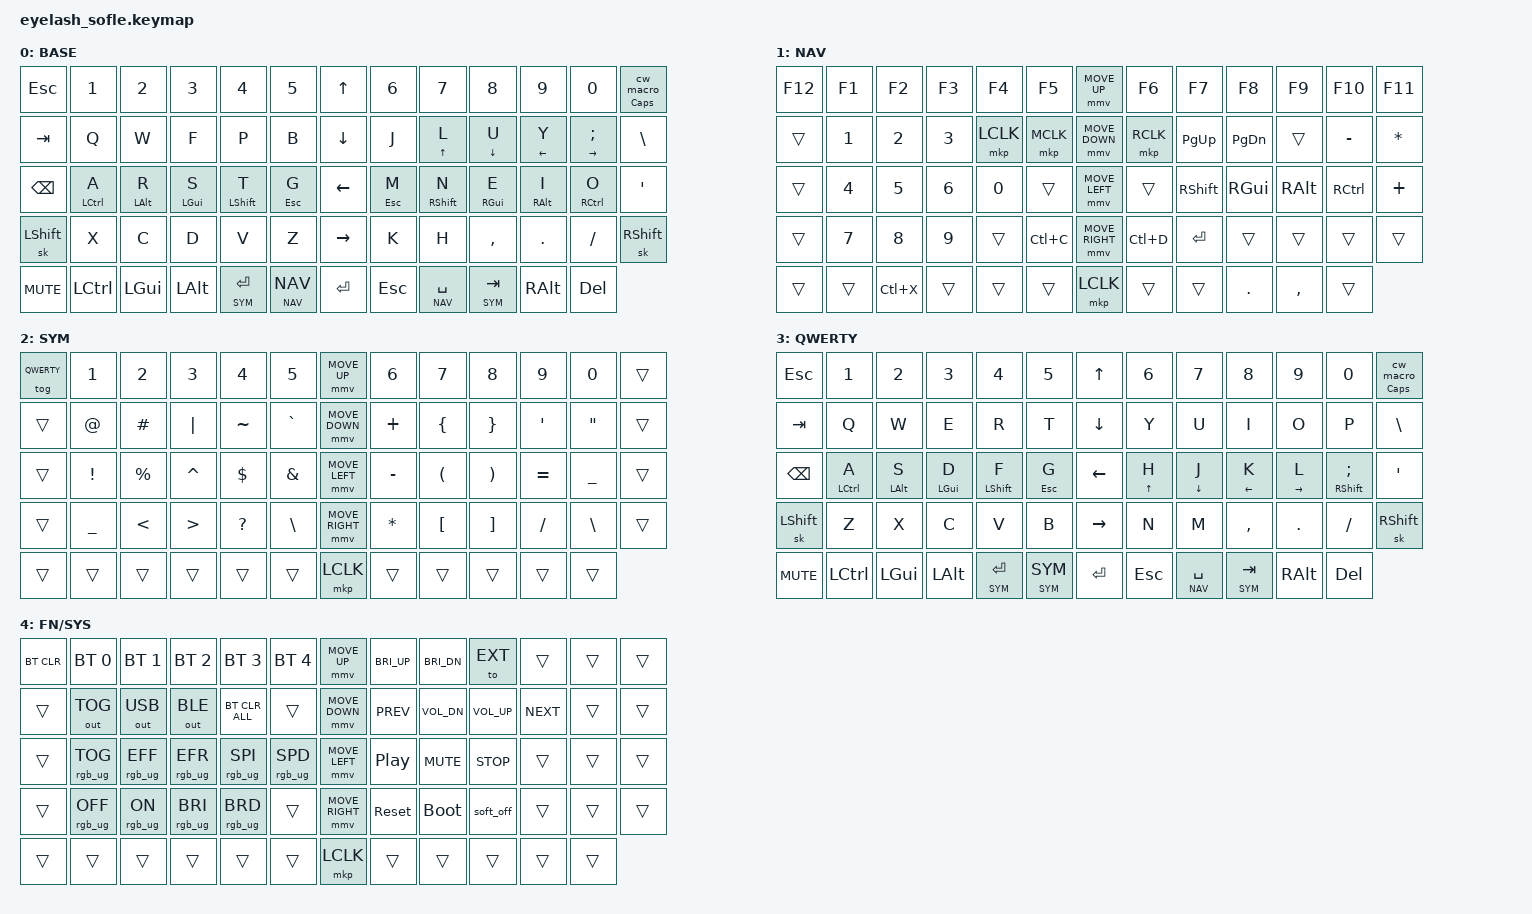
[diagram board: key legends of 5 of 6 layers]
/*
 * Eyelash Sofle — ZMK keymap (synchronized with kanata.kbd)
 *
 * Layers:
 *   0 = BASE    Colemak-DH + HRMs + top-row hold-arrows
 *   1 = NAV     Navigation / numpad / clipboard shortcuts
 *   2 = SYM     Symbols (+ pos 0 toggles QWERTY)
 *   3 = QWERTY  QWERTY alpha layer (toggle via SYM, pos 0)
 *   4 = FN      Function / media / BT / RGB / system (tri-layer NAV+SYM)
 *   5 = EXT     Extended / special keys (toggle via FN, &to EXT)
 *
 * Thumb cluster (outer -> inner, 6 per side):
 *   L: MUTE | CTRL | GUI | ALT | ENTER/SYM | NAV (mo/sticky)
 *   R: ENTER | ESC | SPACE/NAV | TAB/SYM | RALT | DEL
 *
 * Home-row & top-row holds (BASE Colemak-DH):
 *   L (mods):   A=Ctrl  R=Alt  S=GUI  T=Shift (hsl)   G=ESC (hla)
 *   R (arrows): L=UP    U=DOWN  Y=LEFT  ;=RIGHT (top row)
 *   R (mods):   M=ESC   N=Shift (hsr)  E=GUI (hmr)  I=Alt (hmr)  O=Ctrl (hmr) (home row)
 *
 * Home-row holds (QWERTY):
 *   L (mods):   A=Ctrl  S=Alt  D=GUI  F=Shift (hsl)   G=ESC (hla)
 *   R (arrows): H=UP    J=DOWN  K=LEFT  L=RIGHT  ;=Shift (hsr)
 *
 * Combos (DISABLED — kept in source for easy re-enable):
 *   J+K       -> ESC
 *   M+,       -> TAB
 *   C+V       -> Caps Word
 *   14+28+40  -> soft_off (power down)
 */

#define ZMK_POINTING_DEFAULT_MOVE_VAL 1200
#define ZMK_POINTING_DEFAULT_SCRL_VAL 25

#include <input/processors.dtsi>
#include <zephyr/dt-bindings/input/input-event-codes.h>
#include <behaviors.dtsi>
#include <dt-bindings/zmk/bt.h>
#include <dt-bindings/zmk/keys.h>
#include <dt-bindings/zmk/outputs.h>
#include <dt-bindings/zmk/pointing.h>
#include <dt-bindings/zmk/rgb.h>

/* Layer aliases (must match declaration order in keymap { } below). */
#define BASE   0
#define NAV    1
#define SYM    2
#define QWERTY 3
#define FN     4
#define EXT    5

/* ---- Reusable row fragments (expanded by the C preprocessor) ----
 * Edit a fragment here and every layer that uses it updates at once. */
#define LMODS  &kp LCTRL &kp LALT &kp LGUI &kp LSHFT               /* row3 mods, pos 27-30 */
#define EDIT   &kp K_UNDO &kp K_CUT &kp K_COPY &kp K_PASTE &kp K_REDO /* row4 edit, pos 40-44 */

/* Trackball center column (one binding per row; centralized for retuning). */
#define TB_U   &mmv MOVE_UP
#define TB_D   &mmv MOVE_DOWN
#define TB_L   &mmv MOVE_LEFT
#define TB_R   &mmv MOVE_RIGHT
#define TB_CLK &mkp LCLK

/* ------------------------------------------------------------------
 * Pointing devices (trackball + scroll wheel) — kept from prior tuning.
 * ------------------------------------------------------------------ */
&mmv_input_listener { input-processors = <&zip_xy_scaler 2 1>; };
&msc_input_listener { input-processors = <&zip_scroll_scaler 2 1>; };

&msc {
    acceleration-exponent = <1>;
    time-to-max-speed-ms  = <100>;
    delay-ms              = <0>;
};

&mmv {
    time-to-max-speed-ms  = <500>;
    acceleration-exponent = <1>;
    trigger-period-ms     = <16>;
};

&soft_off { hold-time-ms = <2000>; };

/* Caps-word continuation: let it survive common word separators. */
&caps_word { continue-list = <UNDERSCORE MINUS BACKSPACE DELETE>; };

/* Sticky keys ignore other modifiers — allows sequential sticky stacking
 * (e.g. hold A=Ctrl, release, hold R=Alt, release, tap key → Ctrl+Alt+key). */
&sk { ignore-modifiers; };

/ {
    /* Tri-layer: holding NAV and SYM simultaneously activates FN. */
    conditional_layers {
        compatible = "zmk,conditional-layers";
        tri_layer {
            if-layers = <NAV SYM>;
            then-layer = <FN>;
        };
    };

    scroll_encoder: scroll_encoder {
        compatible = "zmk,behavior-sensor-rotate";
        #sensor-binding-cells = <0>;
        bindings = <&msc SCRL_DOWN>, <&msc SCRL_UP>;
        tap-ms = <100>;
    };

    behaviors {
        /* Home-row mods (left hand) — Ctrl / Alt / GUI only (A / R / S).
         *
         *   Tap  = letter
         *   Hold + other key + release  = Ctrl/Alt/GUI + that key
         *   Hold + release alone        = sticky mod for the NEXT keypress only
         *
         * - balanced flavor is forgiving for fast typists
         * - require-prior-idle-ms prevents mods after rolling letters
         *   (kept strict at 150 — you press these deliberately, with a pause;
         *    SHIFT is split onto `hsl` below so fast-typing holds still register)
         * - hold-trigger-key-positions = only the OTHER hand
         * - hold-trigger-on-release keeps rolls from accidentally modding
         */
        hml: home_row_mod_left {
            compatible = "zmk,behavior-hold-tap";
            #binding-cells = <2>;
            flavor = "balanced";
            tapping-term-ms = <220>;
            quick-tap-ms = <175>;
            require-prior-idle-ms = <150>;
            bindings = <&sk>, <&kp>;
            hold-trigger-key-positions = <
                /* Full right hand */
                6  7  8  9  10 11 12
                19 20 21 22 23 24 25
                32 33 34 35 36 37 38
                45 46 47 48 49 50 51
                58 59 60 61 62 63
                /* Other left-hand HRM keys — A+R+S+T can chord together */
                27 28 29 30
            >;
            hold-trigger-on-release;
        };

        /* Left-hand SHIFT (T on Colemak, F on QWERTY) — same as hml but tuned
         * so a deliberate long-press registers even in the middle of a fast
         * burst. require-prior-idle-ms is removed (0) because Shift is the one
         * mod you fire mid-word to capitalize, so it must NOT be force-resolved
         * to a tap just because you pressed a key <150ms earlier.
         *
         * Roll protection is still provided by the opposite-hand positional
         * guard + hold-trigger-on-release (same-hand rolls won't shift).
         * If you ever get accidental capitals on fast opposite-hand rolls,
         * raise require-prior-idle-ms here to ~50.
         */
        hsl: home_shift_left {
            compatible = "zmk,behavior-hold-tap";
            #binding-cells = <2>;
            flavor = "balanced";
            tapping-term-ms = <220>;
            quick-tap-ms = <175>;
            require-prior-idle-ms = <0>;
            bindings = <&sk>, <&kp>;
            hold-trigger-key-positions = <
                /* Full right hand */
                6  7  8  9  10 11 12
                19 20 21 22 23 24 25
                32 33 34 35 36 37 38
                45 46 47 48 49 50 51
                58 59 60 61 62 63
                /* Other left-hand HRM keys — can chord together */
                27 28 29 30
            >;
            hold-trigger-on-release;
        };

        /* Right-hand mods (E=GUI, I=Alt, O=Ctrl on Colemak). */
        hmr: home_row_mod_right {
            compatible = "zmk,behavior-hold-tap";
            #binding-cells = <2>;
            flavor = "balanced";
            tapping-term-ms = <220>;
            quick-tap-ms = <175>;
            require-prior-idle-ms = <150>;
            bindings = <&sk>, <&kp>;
            hold-trigger-key-positions = <
                0  1  2  3  4  5
                13 14 15 16 17 18
                26 27 28 29 30 31
                39 40 41 42 43 44
                52 53 54 55 56 57
                /* Other right-hand HRM keys — can chord together */
                34 35 36 37
            >;
            hold-trigger-on-release;
        };

        /* Right-hand SHIFT (N on Colemak, ; on QWERTY).
         * require-prior-idle-ms is 0 so fast capitalizations work mid-burst. */
        hsr: home_shift_right {
            compatible = "zmk,behavior-hold-tap";
            #binding-cells = <2>;
            flavor = "balanced";
            tapping-term-ms = <220>;
            quick-tap-ms = <175>;
            require-prior-idle-ms = <0>;
            bindings = <&sk>, <&kp>;
            hold-trigger-key-positions = <
                0  1  2  3  4  5
                13 14 15 16 17 18
                26 27 28 29 30 31
                39 40 41 42 43 44
                52 53 54 55 56 57
                /* Other right-hand HRM keys — can chord together */
                34 35 36 37
            >;
            hold-trigger-on-release;
        };

        /* Right-hand hold-arrows (top row Colemak, home row QWERTY) & hold-ESC (M):
         * tap = letter, hold = arrow/esc.
         * Opposite-hand guard ensures same-hand rolls type letters rather than firing arrows.
         */
        hra: home_row_arrow {
            compatible = "zmk,behavior-hold-tap";
            #binding-cells = <2>;
            flavor = "balanced";
            tapping-term-ms = <200>;
            quick-tap-ms = <175>;
            require-prior-idle-ms = <150>;
            bindings = <&kp>, <&kp>;
            hold-trigger-key-positions = <
                0  1  2  3  4  5
                13 14 15 16 17 18
                26 27 28 29 30 31
                39 40 41 42 43 44
                52 53 54 55 56 57
            >;
            hold-trigger-on-release;
        };

        /* Left-hand hold-arrow: same as hra but triggers on RIGHT hand.
         * Used for G=ESC (left inner column, needs right-hand pairing).
         * Used ONLY by G, so require-prior-idle-ms is set to 0 directly so a
         * long-press reliably yields Esc during fast typing.
         */
        hla: home_left_arrow {
            compatible = "zmk,behavior-hold-tap";
            #binding-cells = <2>;
            flavor = "balanced";
            tapping-term-ms = <200>;
            quick-tap-ms = <175>;
            require-prior-idle-ms = <0>;
            bindings = <&kp>, <&kp>;
            hold-trigger-key-positions = <
                6  7  8  9  10 11 12
                19 20 21 22 23 24 25
                32 33 34 35 36 37 38
                45 46 47 48 49 50 51
                58 59 60 61 62 63
            >;
            hold-trigger-on-release;
        };

        /* Layer-tap tuned for thumbs: snappier hold. */
        lt_thumb: layer_tap_thumb {
            compatible = "zmk,behavior-hold-tap";
            #binding-cells = <2>;
            flavor = "tap-preferred";
            tapping-term-ms = <180>;
            quick-tap-ms = <150>;
            bindings = <&mo>, <&kp>;
        };

        /* "Smart" layer thumb:
         *   hold = momentary layer (&mo)
         *   tap  = sticky one-shot layer (&sl)
         *
         * Usage: &ltq <layer> <layer>    (same layer twice)
         *
         * Behavior:
         *   - Press and hold → layer is active while held, releases when you let go
         *     (standard momentary).
         *   - Quick press and release (< tapping-term-ms) with NO other key pressed
         *     → layer is sticky: the very next keypress is interpreted on that layer,
         *     then the layer auto-releases.
         *   - Press, then press another key before releasing → acts as momentary
         *     (the held-down layer is what the other key lands on).
         *
         * "balanced" flavor + quick-tap-ms=0 so consecutive taps feel predictable.
         */
        ltq: layer_tap_or_sticky {
            compatible = "zmk,behavior-hold-tap";
            #binding-cells = <2>;
            flavor = "balanced";
            tapping-term-ms = <200>;
            quick-tap-ms = <0>;
            bindings = <&mo>, <&sl>;
        };

        /* Tap = kp, Hold = sticky layer.
         *
         *   Usage: &kp_slh <layer> <keycode>
         *
         *   - Quick tap and release               → kp (e.g. ENTER)
         *   - Hold past tapping term, press key   → that key lands on <layer>
         *     (feels like a momentary layer — sticky fires first, next key uses it)
         *   - Hold past tapping term, release     → <layer> is sticky for the next
         *     keypress; then auto-releases.
         *
         *   'balanced' + require-prior-idle-ms keep it from firing as a sticky layer
         *   during fast typing.
         */
        kp_slh: kp_tap_sticky_layer_hold {
            compatible = "zmk,behavior-hold-tap";
            #binding-cells = <2>;
            flavor = "balanced";
            tapping-term-ms = <150>;
            quick-tap-ms = <120>;
            require-prior-idle-ms = <100>;
            bindings = <&sl>, <&kp>;
        };

        /* Tap = Caps Word, Hold = Caps Lock.
         *
         *   Usage: &cw_caps CAPS 0
         *     - hold side (&kp) receives CAPS  -> tap-and-hold = Caps Lock
         *     - tap  side (&cw_macro) receives the dummy 0, which it ignores,
         *       and fires &caps_word.
         *
         * Why the macro? &caps_word is a zero-parameter behavior, so it cannot
         * sit directly in a hold-tap's tap slot (the hold-tap always feeds one
         * parameter to each side, exactly like `ltq` does with &mo/&sl). The
         * one-param macro `cw_macro` below absorbs that parameter so caps_word
         * can be nested.
         *
         * tap-preferred so a quick tap reliably yields Caps Word, while a
         * deliberate hold gives Caps Lock (holding also sidesteps the macOS
         * "caps tapped too fast doesn't register" quirk, since hold is longer).
         */
        cw_caps: caps_word_tap_caps_hold {
            compatible = "zmk,behavior-hold-tap";
            #binding-cells = <2>;
            flavor = "tap-preferred";
            tapping-term-ms = <200>;
            quick-tap-ms = <150>;
            bindings = <&kp>, <&cw_macro>;
        };
    };

    macros {
        /* One-parameter wrapper so the zero-param &caps_word behavior can be
         * placed in a hold-tap's tap slot (see cw_caps above). The incoming
         * parameter is accepted to satisfy the cell count and then ignored. */
        cw_macro: cw_macro {
            compatible = "zmk,behavior-macro-one-param";
            #binding-cells = <1>;
            bindings = <&caps_word>;
        };
    };

/*
*    combos {
*        compatible = "zmk,combos";
*
*        combo_softoff {
*            bindings = <&soft_off>;
*            key-positions = <14 28 40>;
*            layers = <BASE QWERTY>;
*        };
*
*        combo_esc {
*            bindings = <&kp ESC>;
*            key-positions = <20 21>;   // J + K
*            timeout-ms = <40>;
*            layers = <BASE QWERTY>;
*        };
*
*        combo_tab {
*            bindings = <&kp TAB>;
*            key-positions = <34 35>;   // M + ,
*            timeout-ms = <40>;
*            layers = <BASE QWERTY>;
*        };
*
*        combo_caps_word {
*            bindings = <&caps_word>;
*            key-positions = <29 30>;   // C + V
*            timeout-ms = <40>;
*            layers = <BASE QWERTY>;
*        };
*    };
*/

    keymap {
        compatible = "zmk,keymap";

        /* ==================================================================
         * LAYER 0 — BASE (Colemak-DH)
         * ================================================================== */
        base_layer {
            display-name = "BASE";
            bindings = <
&kp ESC        &kp N1         &kp N2         &kp N3        &kp N4              &kp N5            &kp UP_ARROW      &kp N6              &kp N7         &kp N8        &kp N9         &kp N0            &cw_caps CAPS 0
&kp TAB        &kp Q          &kp W          &kp F         &kp P               &kp B             &kp DOWN_ARROW    &kp J               &hra UP L      &hra DOWN U   &hra LEFT Y    &hra RIGHT SEMI   &kp BSLH
&kp BACKSPACE  &hml LCTRL A   &hml LALT R    &hml LGUI S   &hsl LSHFT T        &hla ESC G        &kp LEFT_ARROW    &hra ESC M          &hsr RSHFT N   &hmr RGUI E   &hmr RALT I    &hmr RCTRL O      &kp APOS
&sk LSHFT      &kp X          &kp C          &kp D         &kp V               &kp Z             &kp RIGHT_ARROW   &kp K               &kp H          &kp COMMA     &kp DOT        &kp FSLH          &sk RSHFT
&kp C_MUTE     &kp LCTRL      &kp LGUI       &kp LALT      &kp_slh SYM ENTER   &ltq NAV NAV      &kp ENTER         &kp ESC   &kp_slh NAV SPACE        &lt_thumb SYM TAB  &kp RALT  &kp DEL
            >;
            sensor-bindings = <&inc_dec_kp C_VOLUME_UP C_VOL_DN>;
        };

        /* ==================================================================
         * LAYER 1 — NAV
         *   Mirrors kanata.kbd nav layer:
         *   - Left hand: Numpad (1-9), mouse clicks (L/M/R), Cut/Copy/Dup
         *   - Right hand: PgUp/PgDn, mods (Shift/GUI/Alt/Ctrl), Return, +, *
         * ================================================================== */
        nav_layer {
            display-name = "NAV";
            bindings = <
&kp F12     &kp F1      &kp F2      &kp F3      &kp F4      &kp F5      TB_U     &kp F6      &kp F7      &kp F8      &kp F9      &kp F10     &kp F11
&trans      &kp N1      &kp N2      &kp N3      &mkp LCLK   &mkp MCLK   TB_D     &mkp RCLK   &kp PG_UP   &kp PG_DN   &trans      &kp MINUS   &kp ASTRK
&trans      &kp N4      &kp N5      &kp N6      &kp N0      &trans      TB_L     &trans      &kp RSHFT   &kp RGUI    &kp RALT    &kp RCTRL   &kp PLUS
&trans      &kp N7      &kp N8      &kp N9      &trans      &kp LC(C)   TB_R     &kp LC(D)   &kp ENTER   &trans      &trans      &trans      &trans
&trans      &trans      &kp LC(X)   &trans      &trans      &trans      TB_CLK   &trans      &trans      &kp DOT     &kp COMMA   &trans
            >;
            sensor-bindings = <&scroll_encoder>;
        };

        /* ==================================================================
         * LAYER 2 — SYM
         *   Top-left (pos 0) toggles QWERTY (mirrors kanata @tog_qw).
         *   Symbol layout mirrors kanata.kbd.
         * ================================================================== */
        sym_layer {
            display-name = "SYM";
            bindings = <
&tog QWERTY     &kp N1      &kp N2      &kp N3      &kp N4      &kp N5      TB_U     &kp N6       &kp N7       &kp N8       &kp N9       &kp N0       &trans
&trans          &kp AT     &kp HASH    &kp PIPE    &kp TILDE   &kp GRAVE   TB_D     &kp PLUS     &kp LBRC     &kp RBRC     &kp APOS     &kp DQT      &trans
&trans          &kp EXCL   &kp PRCNT   &kp CARET   &kp DLLR    &kp AMPS    TB_L     &kp MINUS    &kp LPAR     &kp RPAR     &kp EQUAL    &kp UNDER    &trans
&trans          &kp UNDER  &kp LT      &kp GT      &kp QMARK   &kp BSLH    TB_R     &kp ASTRK    &kp LBKT     &kp RBKT     &kp FSLH     &kp BSLH     &trans
&trans          &trans     &trans      &trans      &trans      &trans      TB_CLK   &trans       &trans       &trans       &trans       &trans
            >;
            sensor-bindings = <&scroll_encoder>;
        };

        /* ==================================================================
         * LAYER 3 — QWERTY (toggle via SYM pos 0)
         *   Thumb cluster opens SYM; SYM pos 0 (&tog QWERTY) toggles back to BASE.
         * ================================================================== */
        qwerty_layer {
            display-name = "QWERTY";
            bindings = <
&kp ESC        &kp N1         &kp N2        &kp N3         &kp N4              &kp N5            &kp UP_ARROW      &kp N6              &kp N7         &kp N8        &kp N9         &kp N0            &cw_caps CAPS 0
&kp TAB        &kp Q          &kp W         &kp E          &kp R               &kp T             &kp DOWN_ARROW    &kp Y               &kp U          &kp I         &kp O          &kp P             &kp BSLH
&kp BACKSPACE  &hml LCTRL A   &hml LALT S   &hml LGUI D    &hsl LSHFT F        &hla ESC G        &kp LEFT_ARROW    &hra UP H           &hra DOWN J    &hra LEFT K   &hra RIGHT L   &hsr RSHFT SEMI   &kp APOS
&sk LSHFT      &kp Z          &kp X         &kp C          &kp V               &kp B             &kp RIGHT_ARROW   &kp N               &kp M          &kp COMMA     &kp DOT        &kp FSLH          &sk RSHFT
&kp C_MUTE     &kp LCTRL      &kp LGUI      &kp LALT       &kp_slh SYM ENTER   &ltq SYM SYM      &kp ENTER         &kp ESC   &kp_slh NAV SPACE        &lt_thumb SYM TAB   &kp RALT  &kp DEL
            >;
            sensor-bindings = <&inc_dec_kp C_VOLUME_UP C_VOL_DN>;
        };

        /* ==================================================================
         * LAYER 4 — FN / Media / System / BT   (tri-layer NAV+SYM)
         *   All the "rare" stuff: bluetooth, RGB, resets, output toggle,
         *   media controls.
         * ================================================================== */
        fn_layer {
            display-name = "FN/SYS";
            bindings = <
&bt BT_CLR &bt BT_SEL 0     &bt BT_SEL 1      &bt BT_SEL 2     &bt BT_SEL 3     &bt BT_SEL 4      TB_U             &kp C_BRI_UP  &kp C_BRI_DN  &to EXT      &trans  &trans  &trans
&trans     &out OUT_TOG     &out OUT_USB      &out OUT_BLE     &bt BT_CLR_ALL   &trans            TB_D             &kp C_PREV    &kp C_VOL_DN  &kp C_VOL_UP &kp C_NEXT &trans &trans
&trans     &rgb_ug RGB_TOG  &rgb_ug RGB_EFF   &rgb_ug RGB_EFR  &rgb_ug RGB_SPI  &rgb_ug RGB_SPD   TB_L             &kp C_PP      &kp C_MUTE    &kp C_STOP   &trans  &trans  &trans
&trans     &rgb_ug RGB_OFF  &rgb_ug RGB_ON    &rgb_ug RGB_BRI  &rgb_ug RGB_BRD  &trans            TB_R             &sys_reset    &bootloader   &soft_off    &trans  &trans  &trans
&trans     &trans           &trans            &trans           &trans           &trans            TB_CLK           &trans        &trans        &trans       &trans  &trans
            >;
            sensor-bindings = <&scroll_encoder>;
        };

        /* ==================================================================
         * LAYER 5 — EXT / Special keys   (toggle in: FN layer, top-right &to EXT)
         *
         *   The keys a small split has no room for on the main layers:
         *   Print Screen, Scroll Lock, Pause/Break, Insert, Num Lock,
         *   the full Home/End/PgUp/PgDn nav cluster, the Application/Menu
         *   key, plus a few genuinely-useful extras (lock screen, clipboard,
         *   Find).
         *
         *   This is a TOGGLE layer (entered with &to EXT, left with &to BASE)
         *   so you don't have to hold anything while reaching for a rarely
         *   used key. Several keys send `&to BASE` so you're never stuck:
         *   top-left, the left ENTER thumb, and the right SPACE thumb.
         *
         *   Right-hand classic 6-key nav block mirrors a TKL:
         *       INS  HOME  PGUP
         *       DEL  END   PGDN
         *   with a dedicated arrow row directly below it.
         * ================================================================== */
        ext_layer {
            display-name = "EXT";
            bindings = <
&to BASE   &kp PSCRN     &kp SLCK      &kp PAUSE_BREAK  &kp KP_NUM    &trans          &kp UP_ARROW     &kp INS       &kp HOME      &kp PG_UP     &trans        &trans        &trans
&trans     &kp F11       &kp F12       &kp K_APP        &kp CAPS      &trans          &kp DOWN_ARROW   &kp DEL       &kp END       &kp PG_DN     &trans        &trans        &trans
&trans     LMODS                                                      &trans          &kp LEFT_ARROW   &kp LEFT      &kp DOWN      &kp UP        &kp RIGHT     &trans        &trans
&trans     EDIT                                                                       &kp RIGHT_ARROW  &kp K_FIND    &kp C_AL_LOCK  &trans        &trans        &trans        &to BASE
&kp C_MUTE &trans        &trans        &trans           &to BASE      &trans          &kp ENTER        &kp ESC       &to BASE      &trans        &trans        &trans
            >;
            sensor-bindings = <&inc_dec_kp C_VOLUME_UP C_VOL_DN>;
        };
    };
};
